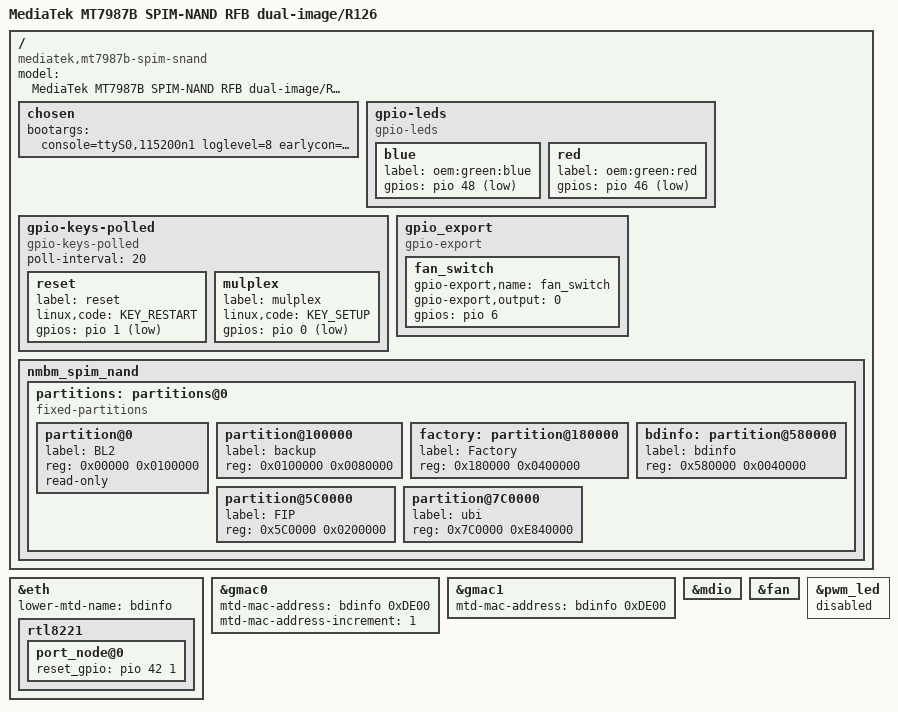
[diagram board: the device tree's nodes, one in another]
/* SPDX-License-Identifier: (GPL-2.0 OR MIT) */

/dts-v1/;
#include "mt7987b.dtsi"
#include "mt7987-netsys-gmac12.dtsi"
#include "mt7987-netsys-gmac1-e2p5g-rtl8221.dtsi"
#include "mt7987-spim-nand.dtsi"
#include <dt-bindings/input/input.h>

/ {
	model = "MediaTek MT7987B SPIM-NAND RFB dual-image/R126";
	compatible = "mediatek,mt7987b-spim-snand",
		     "mediatek,mt7987b", "mediatek,mt7987";

	chosen {
		bootargs = "console=ttyS0,115200n1 loglevel=8  \
			    earlycon=uart8250,mmio32,0x11000000 \
			    pci=pcie_bus_perf";
	};

	gpio-leds {
		compatible = "gpio-leds";

		blue {
			label = "oem:green:blue";
			gpios = <&pio 48 GPIO_ACTIVE_LOW>;
		};

		red {
			label = "oem:green:red";
			gpios = <&pio 46 GPIO_ACTIVE_LOW>;
		};
	};

	gpio-keys-polled {
		compatible = "gpio-keys-polled";
		#address-cells = <1>;
		#size-cells = <0>;
		poll-interval = <20>;

		reset {
			label = "reset";
			linux,code = <KEY_RESTART>;
			gpios = <&pio 1 GPIO_ACTIVE_LOW>;
		};

		mulplex {
			label = "mulplex";
			linux,code = <KEY_SETUP>;
			gpios = <&pio 0 GPIO_ACTIVE_LOW>;
		};
	};

	gpio_export {
		compatible = "gpio-export";
		#size-cells = <0>;

		fan_switch {
			gpio-export,name = "fan_switch";
			gpio-export,output = <0>;
			gpios = <&pio 6 GPIO_ACTIVE_HIGH>;
		};
	};

	nmbm_spim_nand {
		/delete-node/ partitions@0;

		partitions: partitions@0 {
			compatible = "fixed-partitions";
			#address-cells = <1>;
			#size-cells = <1>;

			partition@0 {
				label = "BL2";
				reg = <0x00000 0x0100000>;
				read-only;
			};

			partition@100000 {
				label = "backup";
				reg = <0x0100000 0x0080000>;
			};

			factory: partition@180000 {
				label = "Factory";
				reg = <0x180000 0x0400000>;
			};

			bdinfo: partition@580000 {
				label = "bdinfo";
				reg = <0x580000 0x0040000>;
			};

			partition@5C0000 {
				label = "FIP";
				reg = <0x5C0000 0x0200000>;
			};

			partition@7C0000 {
				label = "ubi";
				reg = <0x7C0000 0xE840000>;
			};
		};
	};
};

&eth {
	lower-mtd-name = "bdinfo";

	rtl8221 {
		status = "ok";
		port_node@0 {
			reset_gpio =  <&pio 42 1>;
		};
	};
};

&gmac0 {
	mtd-mac-address = <&bdinfo 0xDE00>;
	mtd-mac-address-increment = <1>;
};

&gmac1 {
	mtd-mac-address = <&bdinfo 0xDE00>;
};

&mdio {
	/delete-property/ reset-gpios;
	/delete-property/ reset-delay-us;
};

&fan {
	status = "okay";
};

&pwm_led {
	status = "disabled";
};
